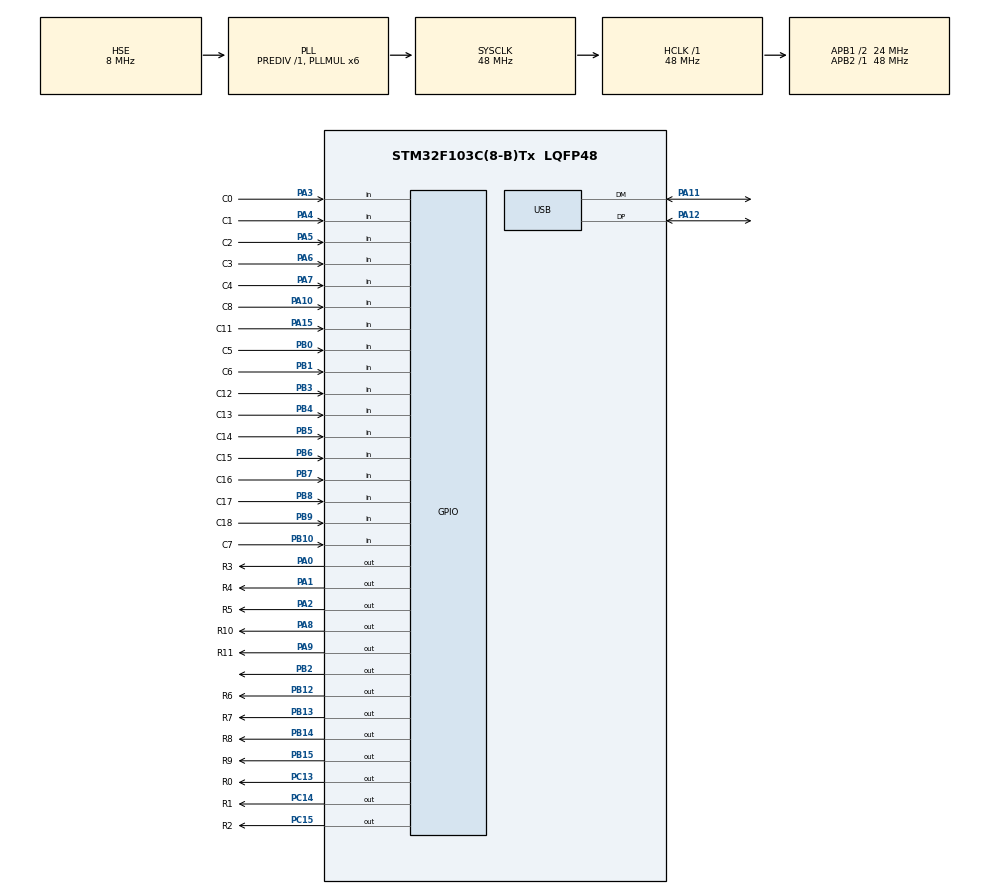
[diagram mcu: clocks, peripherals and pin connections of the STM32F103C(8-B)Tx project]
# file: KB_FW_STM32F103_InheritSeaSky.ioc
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Mcu.Family=STM32F1
Mcu.Name=STM32F103C(8-B)Tx
Mcu.Package=LQFP48
NVIC.PriorityGroup=NVIC_PRIORITYGROUP_4
NVIC.USB_LP_CAN1_RX0_IRQn=true\:0\:0\:false\:false\:true\:false\:true\:true
PA0-WKUP.GPIO_Label=R3
PA0-WKUP.Signal=GPIO_Output
PA1.GPIO_Label=R4
PA1.Signal=GPIO_Output
PA10.GPIO_Label=C8
PA10.GPIO_PuPd=GPIO_PULLUP
PA10.Signal=GPIO_Input
PA11.Mode=Device
PA11.Signal=USB_DM
PA12.Mode=Device
PA12.Signal=USB_DP
PA13.Mode=Serial_Wire
PA13.Signal=SYS_JTMS-SWDIO
PA14.Mode=Serial_Wire
PA14.Signal=SYS_JTCK-SWCLK
PA15.GPIO_Label=C11
PA15.GPIO_PuPd=GPIO_PULLUP
PA15.Signal=GPIO_Input
PA2.GPIO_Label=R5
PA2.Signal=GPIO_Output
PA3.GPIO_Label=C0
PA3.GPIO_PuPd=GPIO_PULLUP
PA3.Signal=GPIO_Input
PA4.GPIO_Label=C1
PA4.GPIO_PuPd=GPIO_PULLUP
PA4.Signal=GPIO_Input
PA5.GPIO_Label=C2
PA5.GPIO_PuPd=GPIO_PULLUP
PA5.Signal=GPIO_Input
PA6.GPIO_Label=C3
PA6.GPIO_PuPd=GPIO_PULLUP
PA6.Signal=GPIO_Input
PA7.GPIO_Label=C4
PA7.GPIO_PuPd=GPIO_PULLUP
PA7.Signal=GPIO_Input
PA8.GPIO_Label=R10
PA8.Signal=GPIO_Output
PA9.GPIO_Label=R11
PA9.Signal=GPIO_Output
PB0.GPIO_Label=C5
PB0.GPIO_PuPd=GPIO_PULLUP
PB0.Signal=GPIO_Input
PB1.GPIO_Label=C6
PB1.GPIO_PuPd=GPIO_PULLUP
PB1.Signal=GPIO_Input
PB10.GPIO_Label=C7
PB10.GPIO_PuPd=GPIO_PULLUP
PB10.Signal=GPIO_Input
PB12.GPIO_Label=R6
PB12.Signal=GPIO_Output
PB13.GPIO_Label=R7
PB13.Signal=GPIO_Output
PB14.GPIO_Label=R8
PB14.Signal=GPIO_Output
PB15.GPIO_Label=R9
PB15.Signal=GPIO_Output
PB2.Signal=GPIO_Output
PB3.GPIO_Label=C12
PB3.GPIO_PuPd=GPIO_PULLUP
PB3.Signal=GPIO_Input
PB4.GPIO_Label=C13
PB4.GPIO_PuPd=GPIO_PULLUP
PB4.Signal=GPIO_Input
PB5.GPIO_Label=C14
PB5.GPIO_PuPd=GPIO_PULLUP
PB5.Signal=GPIO_Input
PB6.GPIO_Label=C15
PB6.GPIO_PuPd=GPIO_PULLUP
PB6.Signal=GPIO_Input
PB7.GPIO_Label=C16
PB7.GPIO_PuPd=GPIO_PULLUP
PB7.Signal=GPIO_Input
PB8.GPIO_Label=C17
PB8.GPIO_PuPd=GPIO_PULLUP
PB8.Signal=GPIO_Input
PB9.GPIO_Label=C18
PB9.GPIO_PuPd=GPIO_PULLUP
PB9.Signal=GPIO_Input
PC13-TAMPER-RTC.GPIO_Label=R0
PC13-TAMPER-RTC.Signal=GPIO_Output
PC14-OSC32_IN.GPIO_Label=R1
PC14-OSC32_IN.Signal=GPIO_Output
PC15-OSC32_OUT.GPIO_Label=R2
PC15-OSC32_OUT.Signal=GPIO_Output
PD0-OSC_IN.Mode=HSE-External-Oscillator
PD0-OSC_IN.Signal=RCC_OSC_IN
PD1-OSC_OUT.Mode=HSE-External-Oscillator
PD1-OSC_OUT.Signal=RCC_OSC_OUT
ProjectManager.HeapSize=0x200
ProjectManager.StackSize=0x400
ProjectManager.TargetToolchain=Makefile
RCC.AHBFreq_Value=48000000
RCC.APB1CLKDivider=RCC_HCLK_DIV2
RCC.APB1Freq_Value=24000000
RCC.APB1TimFreq_Value=48000000
RCC.APB2Freq_Value=48000000
RCC.APB2TimFreq_Value=48000000
RCC.HCLKFreq_Value=48000000
RCC.PLLMUL=RCC_PLL_MUL6
RCC.RTCClockSelection=RCC_RTCCLKSOURCE_HSE_DIV128
RCC.SYSCLKFreq_VALUE=48000000
RCC.SYSCLKSource=RCC_SYSCLKSOURCE_PLLCLK
RCC.USBFreq_Value=48000000
USB_DEVICE.CLASS_NAME_FS=HID
USB_DEVICE.PID_HID_FS=0x572c
USB_DEVICE.VirtualMode=Hid
USB_DEVICE.VirtualModeFS=Hid_FS
VP_RTC_VS_RTC_Activate.Mode=RTC_Enabled
VP_USB_DEVICE_VS_USB_DEVICE_HID_FS.Mode=HID_FS
board=custom

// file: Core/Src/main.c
/* USER CODE BEGIN Header */
/**
  ******************************************************************************
  * @file           : main.c
  * @brief          : Main program body
  ******************************************************************************
  * @attention
  *
  * Copyright (c) 2022 STMicroelectronics.
  * All rights reserved.
  *
  * This software is licensed under terms that can be found in the LICENSE file
  * in the root directory of this software component.
  * If no LICENSE file comes with this software, it is provided AS-IS.
  *
  ******************************************************************************
  */
/* USER CODE END Header */
#include "main.h"
#include "usb_device.h"

/* USER CODE BEGIN Includes */
#include "key_event.h"
#include "bsp_key.h"
/* USER CODE END Includes */

 RTC_HandleTypeDef hrtc;

/* USER CODE BEGIN PV */
// extern USBD_HandleTypeDef hUsbDeviceFS;
uint8_t fac_us;
key_info_t key_info;
/* USER CODE END PV */

void SystemClock_Config(void);
static void MX_GPIO_Init(void);
static void MX_RTC_Init(void);

int main(void)
{

  /* MCU Configuration--------------------------------------------------------*/

  /* Reset of all peripherals, Initializes the Flash interface and the Systick. */
  HAL_Init();

  /* Configure the system clock */
  SystemClock_Config();

  /* Initialize all configured peripherals */
  MX_GPIO_Init();
  MX_RTC_Init();
  MX_USB_DEVICE_Init();
  /* USER CODE BEGIN 2 */
// uint8_t txbuffer[8]= {0x00,0x00,0x00,0x00,0x00,0x00,0x00,0x00};//�?
// uint8_t sendbuffer[8]={0x00,0x00,0x2c,0x00,0x00,0x00,0x00,0x00};//空格
	mx_key_init(&key_info);
	mx_key_init_layer1(&key_info);
  /* USER CODE END 2 */

  /* Infinite loop */
  while (1)
  {

    /* USER CODE BEGIN 3 */
    detect_key_events();
// USBD_HID_SendReport(&hUsbDeviceFS,sendbuffer,8);//发�?�报�?
// HAL_Delay(5000);
  }
  /* USER CODE END 3 */
}

void SystemClock_Config(void)
{
  RCC_OscInitTypeDef RCC_OscInitStruct = {0};
  RCC_ClkInitTypeDef RCC_ClkInitStruct = {0};
  RCC_PeriphCLKInitTypeDef PeriphClkInit = {0};

  /** Initializes the RCC Oscillators according to the specified parameters
  * in the RCC_OscInitTypeDef structure.
  */
  RCC_OscInitStruct.OscillatorType = RCC_OSCILLATORTYPE_HSE;
  RCC_OscInitStruct.HSEState = RCC_HSE_ON;
  RCC_OscInitStruct.HSEPredivValue = RCC_HSE_PREDIV_DIV1;
  RCC_OscInitStruct.HSIState = RCC_HSI_ON;
  RCC_OscInitStruct.PLL.PLLState = RCC_PLL_ON;
  RCC_OscInitStruct.PLL.PLLSource = RCC_PLLSOURCE_HSE;
  RCC_OscInitStruct.PLL.PLLMUL = RCC_PLL_MUL6;
  if (HAL_RCC_OscConfig(&RCC_OscInitStruct) != HAL_OK)
  {
    Error_Handler();
  }

  /** Initializes the CPU, AHB and APB buses clocks
  */
  RCC_ClkInitStruct.ClockType = RCC_CLOCKTYPE_HCLK|RCC_CLOCKTYPE_SYSCLK
                              |RCC_CLOCKTYPE_PCLK1|RCC_CLOCKTYPE_PCLK2;
  RCC_ClkInitStruct.SYSCLKSource = RCC_SYSCLKSOURCE_PLLCLK;
  RCC_ClkInitStruct.AHBCLKDivider = RCC_SYSCLK_DIV1;
  RCC_ClkInitStruct.APB1CLKDivider = RCC_HCLK_DIV2;
  RCC_ClkInitStruct.APB2CLKDivider = RCC_HCLK_DIV1;

  if (HAL_RCC_ClockConfig(&RCC_ClkInitStruct, FLASH_LATENCY_1) != HAL_OK)
  {
    Error_Handler();
  }
  PeriphClkInit.PeriphClockSelection = RCC_PERIPHCLK_RTC|RCC_PERIPHCLK_USB;
  PeriphClkInit.RTCClockSelection = RCC_RTCCLKSOURCE_HSE_DIV128;
  PeriphClkInit.UsbClockSelection = RCC_USBCLKSOURCE_PLL;
  if (HAL_RCCEx_PeriphCLKConfig(&PeriphClkInit) != HAL_OK)
  {
    Error_Handler();
  }
}

static void MX_RTC_Init(void)
{

  /** Initialize RTC Only
  */
  hrtc.Instance = RTC;
  hrtc.Init.AsynchPrediv = RTC_AUTO_1_SECOND;
  hrtc.Init.OutPut = RTC_OUTPUTSOURCE_NONE;
  if (HAL_RTC_Init(&hrtc) != HAL_OK)
  {
    Error_Handler();
  }

}

static void MX_GPIO_Init(void)
{
  GPIO_InitTypeDef GPIO_InitStruct = {0};

  /* GPIO Ports Clock Enable */
  __HAL_RCC_GPIOC_CLK_ENABLE();
  __HAL_RCC_GPIOD_CLK_ENABLE();
  __HAL_RCC_GPIOA_CLK_ENABLE();
  __HAL_RCC_GPIOB_CLK_ENABLE();

  /*Configure GPIO pin Output Level */
  HAL_GPIO_WritePin(GPIOC, R0_Pin|R1_Pin|R2_Pin, GPIO_PIN_RESET);

  /*Configure GPIO pin Output Level */
  HAL_GPIO_WritePin(GPIOA, R3_Pin|R4_Pin|R5_Pin|R10_Pin
                          |R11_Pin, GPIO_PIN_RESET);

  /*Configure GPIO pin Output Level */
  HAL_GPIO_WritePin(GPIOB, GPIO_PIN_2|R6_Pin|R7_Pin|R8_Pin
                          |R9_Pin, GPIO_PIN_RESET);

  /*Configure GPIO pins : R0_Pin R1_Pin R2_Pin */
  GPIO_InitStruct.Pin = R0_Pin|R1_Pin|R2_Pin;
  GPIO_InitStruct.Mode = GPIO_MODE_OUTPUT_PP;
  GPIO_InitStruct.Pull = GPIO_NOPULL;
  GPIO_InitStruct.Speed = GPIO_SPEED_FREQ_LOW;
  HAL_GPIO_Init(GPIOC, &GPIO_InitStruct);

  /*Configure GPIO pins : R3_Pin R4_Pin R5_Pin R10_Pin
                           R11_Pin */
  GPIO_InitStruct.Pin = R3_Pin|R4_Pin|R5_Pin|R10_Pin
                          |R11_Pin;
  GPIO_InitStruct.Mode = GPIO_MODE_OUTPUT_PP;
  GPIO_InitStruct.Pull = GPIO_NOPULL;
  GPIO_InitStruct.Speed = GPIO_SPEED_FREQ_LOW;
  HAL_GPIO_Init(GPIOA, &GPIO_InitStruct);

  /*Configure GPIO pins : C0_Pin C1_Pin C2_Pin C3_Pin
                           C4_Pin C8_Pin C11_Pin */
  GPIO_InitStruct.Pin = C0_Pin|C1_Pin|C2_Pin|C3_Pin
                          |C4_Pin|C8_Pin|C11_Pin;
  GPIO_InitStruct.Mode = GPIO_MODE_INPUT;
  GPIO_InitStruct.Pull = GPIO_PULLUP;
  HAL_GPIO_Init(GPIOA, &GPIO_InitStruct);

  /*Configure GPIO pins : C5_Pin C6_Pin C7_Pin C12_Pin
                           C13_Pin C14_Pin C15_Pin C16_Pin
                           C17_Pin C18_Pin */
  GPIO_InitStruct.Pin = C5_Pin|C6_Pin|C7_Pin|C12_Pin
                          |C13_Pin|C14_Pin|C15_Pin|C16_Pin
                          |C17_Pin|C18_Pin;
  GPIO_InitStruct.Mode = GPIO_MODE_INPUT;
  GPIO_InitStruct.Pull = GPIO_PULLUP;
  HAL_GPIO_Init(GPIOB, &GPIO_InitStruct);

  /*Configure GPIO pins : PB2 R6_Pin R7_Pin R8_Pin
                           R9_Pin */
  GPIO_InitStruct.Pin = GPIO_PIN_2|R6_Pin|R7_Pin|R8_Pin
                          |R9_Pin;
  GPIO_InitStruct.Mode = GPIO_MODE_OUTPUT_PP;
  GPIO_InitStruct.Pull = GPIO_NOPULL;
  GPIO_InitStruct.Speed = GPIO_SPEED_FREQ_LOW;
  HAL_GPIO_Init(GPIOB, &GPIO_InitStruct);

}

void Error_Handler(void)
{
  __disable_irq();
  while (1)
  {
  }
}
